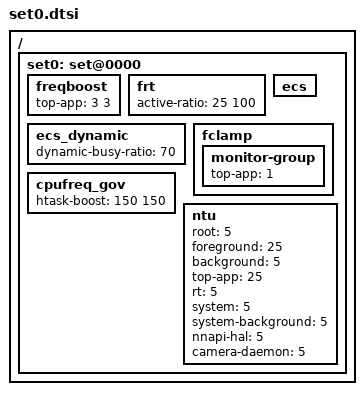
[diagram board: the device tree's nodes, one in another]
/ {
	/* normal mode - default */
	set0: set@0000 {
		/* Boosting margin applied to frequency selection */
		freqboost {			/* LIT BIG */
			top-app			= <  3   3>;
		};

		frt {	   	     		/* LIT BIG */
			active-ratio		= < 25 100>;
		};

		ecs { };

		ecs_dynamic {
			dynamic-busy-ratio		= <70>;
		};

		fclamp {
			monitor-group {
				top-app         = <1>;
			};
		};

		cpufreq_gov {
				/* LIT BIG */
			htask-boost = < 150 150 >;
		};

		ntu {
			root			= <  5 >;
			foreground 		= < 25 >;
			background		= <  5 >;
			top-app			= < 25 >;
			rt			= <  5 >;
			system			= <  5 >;
			system-background	= <  5 >;
			nnapi-hal		= <  5 >;
			camera-daemon		= <  5 >;
		};
	};
};
